# AM13E23019 register map
Vendor: Texas Instruments; File version: 1.0
CPU: CM33 r0p1, little endian, MPU, FPU, VTOR, 4 interrupt priority bits
Registers are 32-bit, read-write, reset 0x0 unless marked. A register's access mark holds for its fields unless they carry their own. Offsets are from the block's base; [hi:lo] are bit positions; lines under a group give offsets from that group; {n}, {i} and the like mark numbered series; 'fields as' and 'values as' point back to an identical list.

## UNICOMM0 — UNICOMM module
Base 0x40630000
Same registers: UNICOMM1 0x40632000, UNICOMM2 0x40634000, UNICOMM3 0x40670000, UNICOMM4 0x40672000, UNICOMM5 0x40674000
0x800 GPRCM group
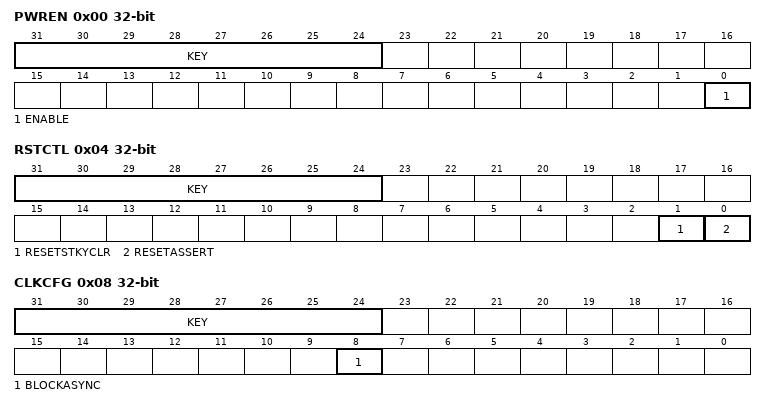
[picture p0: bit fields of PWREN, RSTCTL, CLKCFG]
  0x00 PWREN access per field — Power enable
    [31:24] KEY wo — Key which must be written for the write to take effect.
      38=KEY (Write key.)
    [0] ENABLE rw — Power Enable
      0=DISABLE (Disable Power); 1=ENABLE (Enable Power)
  0x04 RSTCTL access per field — Reset Control
    [31:24] KEY wo — Key which must be written for the write to take effect.
      177=KEY (Write key.)
    [1] RESETSTKYCLR rw — Reset sticky bit clear
      0=NOP (Writing 0 has no effect); 1=CLR (Clear reset sticky bit)
    [0] RESETASSERT rw — Reset assertion to the peripheral
      0=NOP (Writing 0 has no effect); 1=ASSERT (Assert reset)
  0x08 CLKCFG access per field — Peripheral Clock Configuration Register
    [31:24] KEY wo — Key which must be written for the write to take effect.
      169=KEY (Write key.)
    [8] BLOCKASYNC rw — Async Clock Request is blocked from starting SYSOSC or forcing bus clock to 32MHz
      0=DISABLE (Not block async clock request); 1=ENABLE (Block async clock request)
  0x14 STAT ro — Status Register
    [16] RESETSTKY — Reset sticky bit
      0=NORES (The peripheral has not been reset since this bit was last cleared by RESETSTKYCLR in the RSTCTL register); 1=RESET (The peripheral was reset since the last bit clear)
0x1100 IPMODE — Mode Selection Register
  [1:0] SELECT — Free run control
    0=UART (Default functionality is UART); 1=SPI (SPG in SPI Mode); 2=I2C_CONTROLLER (SPG in I2C Controller Mode); 3=I2C_PERIPHERAL (SPG in I2C Peripheral Mode)

## SPG0 — SPGSS module
Base 0x4063F000
Same registers: SPG1 0x4067F000
0x120 UNICOMM_LPBK group
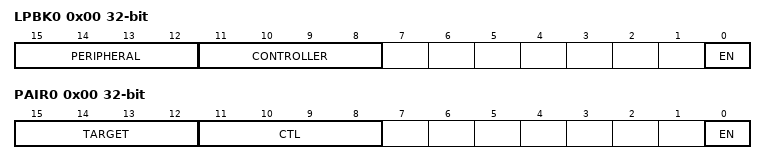
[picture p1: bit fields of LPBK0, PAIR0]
  0x00 LPBK0 — Loopback between SPG instances User has to ensure that the SPGs looped back have the same underlying IP instantiated; i.e. both UART, both SPI, both I2C, etc.,
    [15:12] PERIPHERAL — Select SPG peripheral for loopback. Signals invovled in loopback based on interface chosen 1. SPI : CS, SCLK, SDI, SDO 2. I2C : SCL, SDA 3. UART : TX, RX
      {v}=SPG{v+1} (SPG responder select for loopback.) (v=0..15)
    [11:8] CONTROLLER — Select SPG controller for loopback. Signals invovled in loopback based on interface chosen 1. SPI : CS, SCLK, SDI, SDO 2. I2C : SCL, SDA 3. UART : TX, RX
      {v}=SPG{v+1} (SPG commander select for loopback.) (v=0..15)
    [0] EN — Loopback enable
      0=DISABLE (Does not select this clock as a source); 1=ENABLE (Select this clock as a source)
0x1C0 I2C_PAIR group
  0x00 PAIR0 — Pairing of I2C for MULTI-MASTER/SMBUS applications
    [15:12] TARGET — UNICOMM instance for loopback. This instance will be treated as the target
      {v}=SPG{v+1} (SPG responder select for loopback.) (v=0..15)
    [11:8] CTL — UNICOMM instance for loopback. This instance will be treated as the controller.
      {v}=SPG{v+1} (SPG commander select for loopback.) (v=0..15)
    [0] EN — Enable
      values as UNICOMM_LPBK.LPBK0.EN
0xC00 TEST0
  [3:0] DTB_MUX_SEL — This bit field is used to select DTB mux digital output signals.

## TINIE — TINIELITE module
Base 0x408FF000
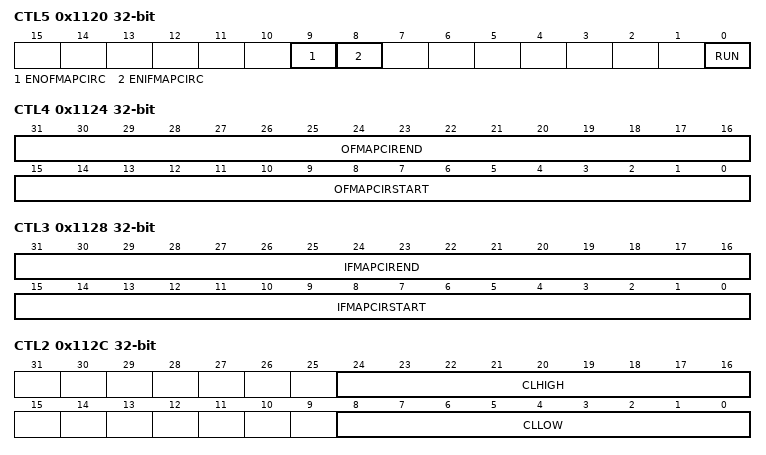
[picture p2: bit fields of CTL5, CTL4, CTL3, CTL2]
0x1120 CTL5
  [9] ENOFMAPCIRC — Enable circular addressing on output feature map read address.
    0=DISABLE (Disable circular buffering on the output feature map); 1=ENABLE (Enable circular buffering on the output feature map)
  [8] ENIFMAPCIRC — Enable circular addressing on input feature map read address.
    0=DISABLE; 1=ENABLE (Enable circular buffering on the input feature map)
  [0] RUN — Start the accelerator. Writing a 1 to this bit starts the accelerator. When the STOP instruction is executed this bit is cleared by hardware and DONE interrupt flag is set.
0x1124 CTL4
  [31:16] OFMAPCIREND — Circular buffer output feature map end address.
  [15:0] OFMAPCIRSTART — Circular buffer output feature map start address.
0x1128 CTL3
  [31:16] IFMAPCIREND — Circular buffer input feature map end address
  [15:0] IFMAPCIRSTART — Circular buffer input feature map start address
0x112C CTL2
  [24:16] CLHIGH — Upper clamp value
  [8:0] CLLOW — Lower clamp value
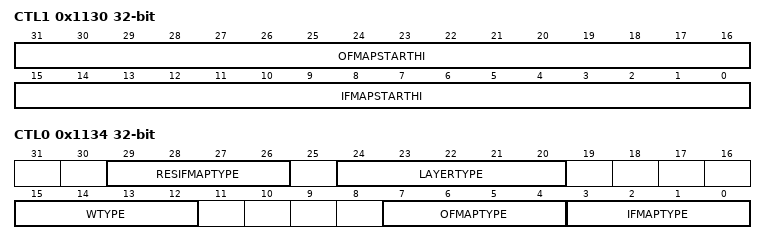
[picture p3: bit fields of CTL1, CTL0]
0x1130 CTL1
  [31:16] OFMAPSTARTHI — Start address (Higher 16 bits) of output feature map data.
  [15:0] IFMAPSTARTHI — Start address (Higher 16 bits) of input feature map data.
0x1134 CTL0
  [29:26] RESIFMAPTYPE — Residual Input feature map type,
    0=UNSIGNED_16BIT; 1=UNSIGNED_8BIT (Unsigned 8 bit data type); 2=UNSIGNED_4BIT (Unsigned 4 bit data type); 8=SIGNED_16BIT; 9=SIGNED_8BIT (Signed 8 bit data type); 10=SIGNED_4BIT (Signed 4 bit data type)
  [24:20] LAYERTYPE
    0=FCONV; 2=DW; 3=PW; 5=CONV; 6=FC; 7=AVGPOOL; 8=MAXPOOL; 16=FCONV_RESIDUAL; 18=DW_RESIDUAL; 19=PW_RESIDUAL; 21=CONV_RESIDUAL; 22=FC_RESIDUAL; 23=AVGPOOL_RESIDUAL; 24=MAXPOOL_RESIDUAL
  [15:12] WTYPE — Weight Type
    0=_2T (+1,-1,0); 1=BINARY (Binary data type, +1 or -1); 2=SIGNED_2BIT (Unsigned 8 bit data type); 3=SIGNED_4BIT (Signed 4 bit data type); 4=SIGNED_8BIT (Signed 8 bit data type)
  [7:4] OFMAPTYPE — Output feature map type.
    0=UNSIGNED_16BIT; 1=UNSIGNED_8BIT (Unsigned 8 bit data type); 2=UNSIGNED_4BIT (Unsigned 4 bit data type); 3=BINARY (Binary data type); 8=SIGNED_16BIT; 9=SIGNED_8BIT (Signed 8 bit data type); 10=SIGNED_4BIT (Signed 4 bit data type)
  [3:0] IFMAPTYPE — Input feature map type,
    values as OFMAPTYPE
0x1138 LCREG group
  {0x0+4j} LC[{j}] (j=0..5) — Loop count registers.
    [15:0] CNT — Loop count.
0x1150 PC — Program count register
  [15:0] VALUE — Program count value.
0x1154 ADDRREG group
  {0x0+4j} AREG[{j}] (j=0..19) — Address registers.
    [15:0] DATA — Data word.
{0x1710+4i} DATAIN[{i}] (i=0..1) access not given — Input Data registers, used to load data from memory.
0x1720 DATAOUT access not given — Output Data registers, used to store data to memory.
0x1730 SS0LOW access not given — Scale and shift register 0, lower 32 bits.
0x1734 SS0HIGH access not given — Scale and shift register 0, upper 32 bits.
0x1738 SS1LOW access not given — Scale and shift register 1, lower 32 bits.
0x173C SS1HIGH access not given — Scale and shift register 1, upper 32 bits.
0x1750 WGHT0LOW access not given — Weight register 0, lower 32 bits.
0x1754 WGHT0HIGH access not given — Weight register 0, upper 32 bits.
0x1758 WGHT1LOW access not given — Weight register 1, lower 32 bits.
0x175C WGHT1HIGH access not given — Weight register 1, upper 32 bits.
0x1C00 ACCREG group
  {0x0+4j} ACCVAL[{j}] (j=0..31) — Register file data.
    [17:0] DATA — Data word.
0x2000 INSTMEM group
  {0x0+4j} INSTMEM[{j}] (j=0..255) access not given — Instruction memory word.
0x2800 REGFILE group
  {0x0+4j} RFDATA[{j}] (j=0..511) access not given — Register file data.
